# LCD_C_208.0 register map
Vendor: Texas Instruments
Peripheral module from a debugger description file (folder msp430).
Registers are 8-bit, access not given, no defined reset value unless marked. A register's access mark holds for its fields unless they carry their own. Offsets are as the file gives them; lines under a group give offsets from that group; [hi:lo] are bit positions; {n}, {i} and the like mark numbered series; 'fields as' and 'values as' point back to an identical list; <NAME> marks a mode.

## LCD_C
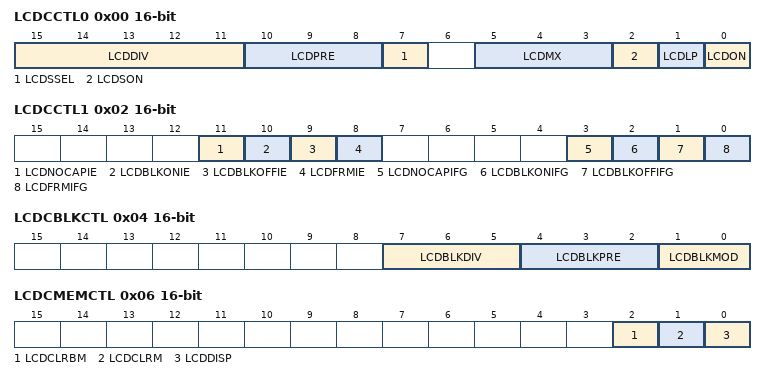
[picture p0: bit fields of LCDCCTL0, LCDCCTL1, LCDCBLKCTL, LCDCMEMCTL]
0x00 LCDCCTL0 16-bit rw — LCD_C control 0
  [15:11] LCDDIV — LCD frequency divider
    {v}=Divide by {v+1} (v=0..31)
  [10:8] LCDPRE — LCD frequency pre-scaler
    0=Divide by 1; 1=Divide by 2; 2=Divide by 4; 3=Divide by 8; 4=Divide by 16; 5=Divide by 32
  [7] LCDSSEL — Clock source select for LCD and blinking frequency
    0=ACLK (ACLK (30 kHz to 40 kHz)); 1=VLOCLK
  [5:3] LCDMX — LCD mux rate
    0=STATIC; {v}={v+1}MUX (v=1..7)
  [2] LCDSON — LCD segments on
    0=OFF (All LCD segments are off); 1=ON (All LCD segments are enabled and on or off according to their corresponding memory location)
  [1] LCDLP — LCD low-power waveform
    0=Standard LCD waveforms on segment and common lines selected; 1=Low-power LCD waveforms on segment and common lines selected
  [0] LCDON
    0=OFF (LCD_C module off); 1=ON (LCD_C module on)
0x02 LCDCCTL1 16-bit rw — LCD_C control 1
  [11] LCDNOCAPIE — No capacitance connected interrupt enable
    0=Interrupt disabled; 1=Interrupt enabled
  [10] LCDBLKONIE — LCD blinking interrupt enable, segments switched on
    0=Interrupt disabled; 1=Interrupt enabled
  [9] LCDBLKOFFIE — LCD blinking interrupt enable, segments switched off
    0=Interrupt disabled; 1=Interrupt enabled
  [8] LCDFRMIE — LCD frame interrupt enable
    0=Interrupt disabled; 1=Interrupt enabled
  [3] LCDNOCAPIFG — No capacitance connected interrupt flag
    0=No interrupt pending; 1=Interrupt pending
  [2] LCDBLKONIFG — LCD blinking interrupt flag, segments switched on
    0=No interrupt pending; 1=Interrupt pending
  [1] LCDBLKOFFIFG — LCD blinking interrupt flag, segments switched off
    0=No interrupt pending; 1=Interrupt pending
  [0] LCDFRMIFG — LCD frame interrupt flag
    0=No interrupt pending; 1=Interrupt pending
0x04 LCDCBLKCTL 16-bit rw — LCD_C blinking control
  [7:5] LCDBLKDIV — Clock divider for blinking frequency
    {v}=Divide by {v+1} (v=0..7)
  [4:2] LCDBLKPRE — Clock pre-scaler for blinking frequency
    0=Divide by 512; 1=Divide by 1024; 2=Divide by 2048; 3=Divide by 4096; 4=Divide by 8162; 5=Divide by 16384; 6=Divide by 32768; 7=Divide by 65536
  [1:0] LCDBLKMOD — Blinking mode
    0=Blinking disabled; 1=Blinking of individual segments as enabled in blinking memory register LCDBMx. In mux mode 5 blinking is disabled.; 2=Blinking of all segments; 3=Switching between display contents as stored in LCDMx and LCDBMx memory registers. In mux mode 5 blinking is disabled.
0x06 LCDCMEMCTL 16-bit rw — LCD_C memory control
  [2] LCDCLRBM — Clear LCD blinking memory
    0=Contents of blinking memory registers LCDBM remain unchanged; 1=Clear content of all blinking memory registers LCDBM
  [1] LCDCLRM — Clear LCD memory
    0=Contents of LCD memory registers LCDMx remain unchanged; 1=Clear content of all LCD memory registers LCDM
  [0] LCDDISP — Select LCD memory registers for display
    0=Display content of LCD memory registers LCDM; 1=Display content of LCD blinking memory registers LCDBM
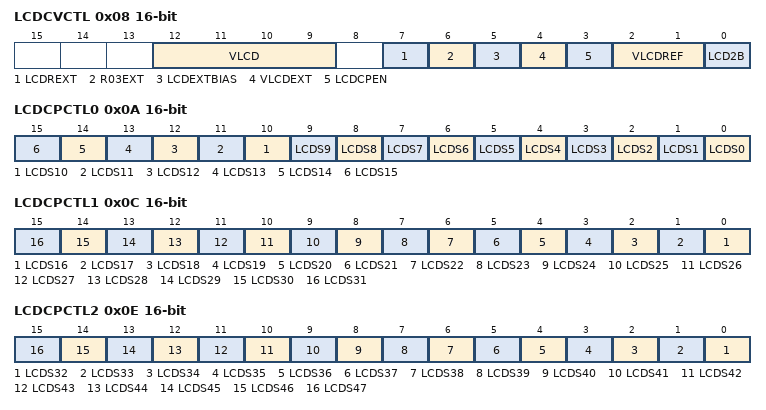
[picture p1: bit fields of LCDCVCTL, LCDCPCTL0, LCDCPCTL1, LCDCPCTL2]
0x08 LCDCVCTL 16-bit rw — LCD_C Voltage Control Register
  [12:9] VLCD — Charge pump voltage select
    0=DISABLED (Charge pump disabled); 1=2_60 (If VLCDREF = 00 or 10: VLCD = 2.60 V; If VLCDREF = 01 or 11: VLCD = 2.17 * VREF); 2=2_66 (If VLCDREF = 00 or 10: VLCD = 2.60 V + (VLCD 1) * 0.06 V; If VLCDREF = 01 or 11: VLCD = 2.17 * VREF + (VLCD 1) * 0.05 * VREF); 3=2_72 (If VLCDREF = 00 or 10: VLCD = 2.60 V + (VLCD 1) * 0.06 V; If VLCDREF = 01 or 11: VLCD = 2.17 * VREF + (VLCD 1) * 0.05 * VREF); 4=2_78 (If VLCDREF = 00 or 10: VLCD = 2.60 V + (VLCD 1) * 0.06 V; If VLCDREF = 01 or 11: VLCD = 2.17 * VREF + (VLCD 1) * 0.05 * VREF); 5=2_84 (If VLCDREF = 00 or 10: VLCD = 2.60 V + (VLCD 1) * 0.06 V; If VLCDREF = 01 or 11: VLCD = 2.17 * VREF + (VLCD 1) * 0.05 * VREF); 6=2_90 (If VLCDREF = 00 or 10: VLCD = 2.60 V + (VLCD 1) * 0.06 V; If VLCDREF = 01 or 11: VLCD = 2.17 * VREF + (VLCD 1) * 0.05 * VREF); 7=2_96 (If VLCDREF = 00 or 10: VLCD = 2.60 V + (VLCD 1) * 0.06 V; If VLCDREF = 01 or 11: VLCD = 2.17 * VREF + (VLCD 1) * 0.05 * VREF); 8=3_02 (If VLCDREF = 00 or 10: VLCD = 2.60 V + (VLCD 1) * 0.06 V; If VLCDREF = 01 or 11: VLCD = 2.17 * VREF + (VLCD 1) * 0.05 * VREF); 9=3_08 (If VLCDREF = 00 or 10: VLCD = 2.60 V + (VLCD 1) * 0.06 V; If VLCDREF = 01 or 11: VLCD = 2.17 * VREF + (VLCD 1) * 0.05 * VREF); 10=3_14 (If VLCDREF = 00 or 10: VLCD = 2.60 V + (VLCD 1) * 0.06 V; If VLCDREF = 01 or 11: VLCD = 2.17 * VREF + (VLCD 1) * 0.05 * VREF); 11=3_20 (If VLCDREF = 00 or 10: VLCD = 2.60 V + (VLCD 1) * 0.06 V; If VLCDREF = 01 or 11: VLCD = 2.17 * VREF + (VLCD 1) * 0.05 * VREF); 12=3_26 (If VLCDREF = 00 or 10: VLCD = 2.60 V + (VLCD 1) * 0.06 V; If VLCDREF = 01 or 11: VLCD = 2.17 * VREF + (VLCD 1) * 0.05 * VREF); 13=3_32 (If VLCDREF = 00 or 10: VLCD = 2.60 V + (VLCD 1) * 0.06 V; If VLCDREF = 01 or 11: VLCD = 2.17 * VREF + (VLCD 1) * 0.05 * VREF); 14=3_38 (If VLCDREF = 00 or 10: VLCD = 2.60 V + (VLCD 1) * 0.06 V; If VLCDREF = 01 or 11: VLCD = 2.17 * VREF + (VLCD 1) * 0.05 * VREF); 15=3_44 (If VLCDREF = 00 or 10: VLCD = 2.60 V + (15 1) * 0.06 V = 3.44 V; If VLCDREF = 01 or 11: VLCD = 2.17 * VREF + (15 1) * 0.05 * VREF = 2.87 * VREF)
  [7] LCDREXT — V2 to V4 voltage on external Rx3 pins
    0=Internally generated V2 to V4 are not switched to pins (LCDEXTBIAS = 0); 1=Internally generated V2 to V4 are switched to pins (LCDEXTBIAS = 0)
  [6] R03EXT — V5 voltage select
    0=VSS (V5 is VSS); 1=R03 (V5 is sourced from the R03 pin)
  [5] LCDEXTBIAS — V2 to V4 voltage select
    0=V2 to V4 are generated internally; 1=V2 to V4 are sourced externally and the internal bias generator is switched off
  [4] VLCDEXT — VLCD source select
    0=VLCD is generated internally; 1=VLCD is sourced externally
  [3] LCDCPEN — Charge pump enable
    0=Charge pump disabled; 1=Charge pump enabled when VLCD is generated internally (VLCDEXT = 0) and VLCD 0 or VLCDREF 0
  [2:1] VLCDREF — Charge pump reference select
    0=Internal reference voltage; 1=External reference voltage; 2=Internal reference voltage switched to external pin LCDREF/R13
  [0] LCD2B — Bias select
    0=1/3 bias; 1=1/2 bias
0x0A LCDCPCTL0 16-bit rw — LCD_C port control 0
  [all] fields
    0=Multiplexed pins are port functions; 1=Pins are LCD functions
  [n] LCDS{n} (n=0..15) — LCD segment line {n} enable
0x0C LCDCPCTL1 16-bit rw — LCD_C port control 1
  [all] fields
    values as the fields of LCDCPCTL0
  [n-16] LCDS{n} (n=16..31) — LCD segment line {n} enable
0x0E LCDCPCTL2 16-bit rw — LCD_C port control 2 (256 segments)
  [all] fields
    values as the fields of LCDCPCTL0
  [n-32] LCDS{n} (n=32..47) — LCD segment line {n} enable
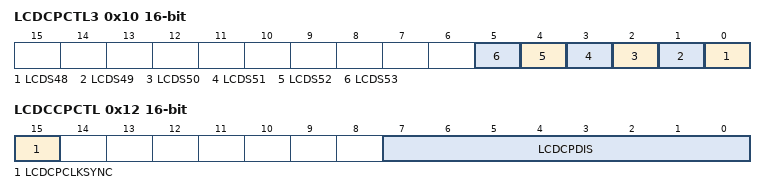
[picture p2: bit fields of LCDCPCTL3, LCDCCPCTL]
0x10 LCDCPCTL3 16-bit rw — LCD_C port control 3 (384 segments)
  [all] fields
    values as the fields of LCDCPCTL0
  [n-48] LCDS{n} (n=48..53) — LCD segment line {n} enable
0x12 LCDCCPCTL 16-bit rw — LCD_C charge pump control
  [15] LCDCPCLKSYNC — LCD charge pump clock synchronization
    0=Synchronization disabled; 1=Synchronization enabled
  [7:0] LCDCPDIS — LCD charge pump disable
0x1E LCDCIV 16-bit ro — LCD_C interrupt vector
  [15:0] LCDCIV — LCD_C interrupt vector value
    0=NONE (No interrupt pending); 2=LCDNOCAPIFG (Interrupt Source: No capacitor connected; Interrupt Flag: LCDNOCAPIFG; Interrupt Priority: Highest); 4=LCDBLKOFFIFG (Interrupt Source: Blink, segments off; Interrupt Flag: LCDBLKOFFIFG); 6=LCDBLKONIFG (Interrupt Source: Blink, segments on; Interrupt Flag: LCDBLKONIFG); 8=LCDFRMIFG (Interrupt Source: Frame interrupt; Interrupt Flag: LCDFRMIFG; Interrupt Priority: Lowest)
{0x1F+i} LCDM{i} (i=1..32) — LCD memory {i}
{0x1F+i} LCDM{i}_LCDBM{i-32} (i=33..43) — LCD memory {i} / LCD blinking memory {i-32}
0x4B LCDM44_LCDBM12 — LCD memory 44 / LCD blinking memory 11
{0x1F+i} LCDM{i}_LCDBM{i-32} (i=45..52) — LCD memory {i} / LCD blinking memory {i-32}
